# M3351 register map
File version: 1.0
Registers are 32-bit, read-write, reset 0x0 unless marked. A register's access mark holds for its fields unless they carry their own. Offsets are from the block's base; [hi:lo] are bit positions.

## DFMC_NSBA — DFMC Register Map
Base 0x5000F000
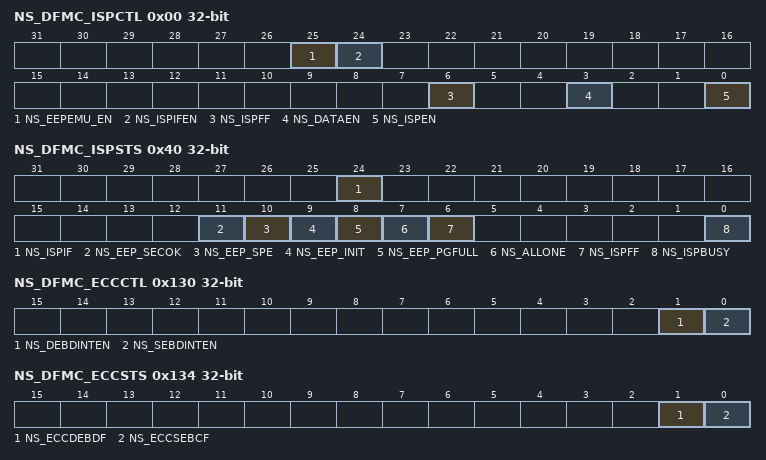
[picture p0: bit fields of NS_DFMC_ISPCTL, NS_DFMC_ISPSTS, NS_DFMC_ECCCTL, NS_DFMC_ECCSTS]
0x00 NS_DFMC_ISPCTL — Non-secure ISP Control Register
  [25] NS_EEPEMU_EN — Non-secure EEP emulation Enable bit (Read Only). This bit is load from (CFG14[6:5])
    0=Non-secure EEPROM emulation Disabled; 1=Non-secure EEPROM emulation Enabled
  [24] NS_ISPIFEN — Non-secure ISP Interrupt Enable bit (Write Protect). Note: This bit is write protected. Refer to the SYS_REGLCTL register.
    0=ISP Interrupt Disabled; 1=ISP Interrupt Enabled
  [6] NS_ISPFF — Non-secure ISP Fail Flag (Write Protect). This bit is set by hardware when a triggered ISP meets any of the following conditions: This bit needs to be cleared by writing 1 to it. Data Flash writes to itself if DATAEN is set to 0. Erase or Program command at brown-out detected. Destination address is illegal, such as exceeding an available range. Invalid ISP commands. Violate the load code read protection. Checksum or Flash All One Verification is not executed in their valid range. Mass erase is not executed in Data Flash. Note: This bit is write protected. Refer to the SYS_REGLCTL register.
  [3] NS_DATAEN — Non-secure Data Flash Update Enable Bit (Write Protect). Note: This bit is write protected. Refer to the SYS_REGLCTL register.
    0=Data Flash cannot be updated; 1=Data Flash can be updated
  [0] NS_ISPEN — Non-secure ISP Enable Bit (Write Protect). ISP function enable bit. Set this bit to enable ISP function. Note: This bit is write protected. Refer to the SYS_REGLCTL register.
    0=ISP function Disabled; 1=ISP function Enabled
0x04 NS_DFMC_ISPADDR — Non-secure ISP Address Register
  [31:0] NS_ISPADDR — Non-secure ISP Address Register. The M3351 is equipped with embedded Data Flash. ISPADDR[1:0] must be kept 00 for ISP 32-bit operation. The ISPADDR[1:0] can be any user wanted value in EEPROM emulate ISP 8 bit program. For CRC32 Checksum Calculation command, this field is the Data Flash starting address for checksum calculation, 4096bytes alignment is necessary for CRC32 checksum calculation. For Data Flash32-bit Program, ISP address needs word alignment (4-byte).
0x08 NS_DFMC_ISPDAT — Non-secure ISP Data Register
  [31:0] NS_ISPDAT — ISP Data. Write data to this register before ISP program operation. Read data from this register after ISP read operation.
0x0C NS_DFMC_ISPCMD — Non-secure ISP Command Register
  [6:0] NS_CMD — Non-secure ISP Command. ISP command table is shown below: The other commands are invalid.
    0=Data FLASH Read; 8=Read Data Flash All-One Result; 11=Read Company ID; 12=Read Device ID; 13=Read Checksum; 33=Data FLASH 32-bit Program; 34=Data FLASH Page Erase. Erase any page in Data Flash; 38=Data FLASH Mass Erase. Erase all pages in Data Flash; 40=Run Data Flash All-One Verification; 45=Run Checksum Calculation; 48=EEPROM emulation 32 bit read; 49=EEPROM emulation 8 bit program; 50=EEPROM emulation 32 bit program; 51=EEPROM emulation initial
0x10 NS_DFMC_ISPTRG — Non-secure ISP Trigger Control Register
  [0] NS_ISPGO — Non-secure ISP Start Trigger (Write Protect). Write 1 to start ISP operation and this bit will be cleared to 0 by hardware automatically when ISP operation is finished. Note: This bit is write protected. Refer to the SYS_REGLCTL register.
    0=ISP operation is finished; 1=ISP is progressed
0x40 NS_DFMC_ISPSTS — Non-secure ISP Status Register
  [24] NS_ISPIF — Non-secure ISP Interrupt Flag (Write Protect). Note: Write 1 to clear this bit.
    0=ISP command not finish or ISP fail flag is 0; 1=ISP command finish or ISP fail is 1
  [11] NS_EEP_SECOK — Non-secure EEPROM Emulation Active and Secure Region Status (Read Only). This bit is set by hardware when EEPROM emulation is enabled and the region is marked as Secure.
    0=Not in EEPROM Secure Mode; 1=In EEPROM Secure Mode
  [10] NS_EEP_SPE — Non-secure EEPROM Emulation SRAM Pairty Check Error (Write Protect)
  [9] NS_EEP_INIT — Non-secure EEPROM Emulation in the Initial Processing
  [8] NS_EEP_PGFULL — Non-secure EEPROM Emulation in the Page Full Processing. This bit is set by hardware if EEPROM program and Flash page full. EEPROM emulation will automatic start the page full processing it need program current EEPPROM emulation SRAM data to next page and Erase current page.
    0=Not in page full processing; 1=In the page full processing
  [7] NS_ALLONE — Non-secure Data Flash All-one Verification Flag. This bit is set by hardware if all of Flash bits are 1, and clear if Flash bits are not all 1 after 'Run Data Flash All-One Verification' complete; this bit also can be clear by writing 1
    0=Data Flash bits are not all 1 after 'Run Data Flash All-One Verification' is complete; 1=All of Data Flash bits are 1 after 'Run Data Flash All-One Verification' is complete
  [6] NS_ISPFF — Non-secure ISP Fail Flag (Write Protect). This bit is the mirror of ISPFF (DFMC_ISPCTL[6]), it needs to be cleared by writing 1 to DFMC_ISPCTL[6] or DFMC_ISPSTS[6]. This bit is set by hardware when a triggered ISP meets any of the following conditions: Data Flash writes to itself if DATAEN is set to 0. Erase or Program command at brown-out detected. Destination address is illegal, such as exceeding an available range. Invalid ISP commands. Violate the load code read protection. Checksum or Flash All One Verification is not executed in their valid range. Mass erase is not executed in Data Flash. Note: This bit is write protected. Refer to the SYS_REGLCTL register.
  [0] NS_ISPBUSY — Non-secure ISP Busy Flag (Read Only). Write 1 to start ISP operation and this bit will be cleared to 0 by hardware automatically when ISP operation is finished. This bit is the mirror of ISPGO(DFMC_ISPTRG[0]).
    0=ISP operation is finished; 1=ISP is progressed
0x90 NS_DFMC_MPDATE — Non-secure ISP Data Error Register
  [6:0] NS_ISPDATE — Non-secure ISP Data Error. Read data from this register after ISP 32-bit read operation or ECCSEBCF(DFMC_ECCSTS[0]) is high can know which bit is error. ISPDATE does not continuously store the position information of ECC errors. Therefore, if the user wants to know which bit generated the error, they need to read it before the next ISP action after an ECC single-bit error occurs, or access that position again. This register is the ECC 7-bit data. Note: This bit is only by ISP read commands when an ECC error occurs.
0x130 NS_DFMC_ECCCTL — Non-secure DFMC Error Code Correction Control
  [1] NS_DEBDINTEN — Non-secure Double Error Bits Detection Interrupt Enable (Write Protect). Note: This bit is write protected. Refer to the SYS_REGLCTL register.
    0=Double Error Bits Detection Interrupt Disabled; 1=Double Error Bits Detection Interrupt Enabled
  [0] NS_SEBDINTEN — Non-secure Single Error Bits Detection Interrupt Enable (Write Protect). Note: This bit is write protected. Refer to the SYS_REGLCTL register.
    0=Single Error Bit Detection Interrupt Disabled; 1=Single Error Bit Detection Interrupt Enabled
0x134 NS_DFMC_ECCSTS — Non-secure DFMC Error Code Correction status
  [1] NS_ECCDEBDF — Non-secure ECC Double Error Bits Detection Flag
    0=DFMC does not detect ECC double error bits fault; 1=DFMC detects ECC double error bits fault
  [0] NS_ECCSEBCF — Non-secure ECC Single Error Bits Correction Flag
    0=DFMC does not detect ECC single error bits fault; 1=DFMC detects and corrects ECC single error bits fault
0x138 NS_DFMC_ECCSEFAR ro — Non-secure DFMC ECC Single Error fault Adress Register
  [31:0] NS_ECCSEFAR — Non-secure ECC Single Error Fault Address Register (Read Only). When DFMC detects a ECCSEBCF(DFMC_ECCSTS[0]) would record fault address at the register. The register is cleared by writing 1 to ECCSEBCF. ECCSEFAR returns the CPU read address, so the lowest two bits of the address may not be zero and should be ignored. Note: During ISP commands 0x0D or 0x08, this register keeps the CRC/All-One check error value captured at that moment.
0x13C NS_DFMC_ECCDEFAR ro — Non-secure DFMC ECC Double Error fault Adress Register
  [31:0] NS_ECCDEFAR — Non-secure ECC Double Error Fault Address Register (Read Only). When DFMC detects a ECCDEBDF(DFMC_ECCSTS[1]) would record fault address at the register. The register is cleared by writing 1 to ECCDEBDF. ECCDEFAR returns the CPU read address, so the lowest two bits of the address may not be zero and should be ignored. Note: During ISP commands 0x0D or 0x08, this register keeps the CRC/All-One check error value captured at that moment.
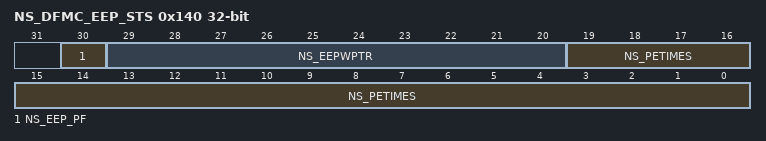
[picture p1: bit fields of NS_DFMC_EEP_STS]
0x140 NS_DFMC_EEP_STS ro — Non-secure DFMC EEPROM Emulation Status Register
  [30] NS_EEP_PF — Non-secure EEPROM Emulation in the Page Full Processing. This bit is set by hardware if EEPROM program and Flash page full. EEPROM emulation will automatically start the page full processing if it needs program current EEPPROM emulation SRAM data to next page and Erase current page.
    0=Not in page full processing; 1=In the page full processing
  [29:20] NS_EEPWPTR — Non-secure Current Page Write Pointer
  [19:0] NS_PETIMES — Non-secure Page Erase Times. Two EEPROM eumlation total erase times.There are two pages in total. So, if the number is 100 it means each page has been erased 50 times.
